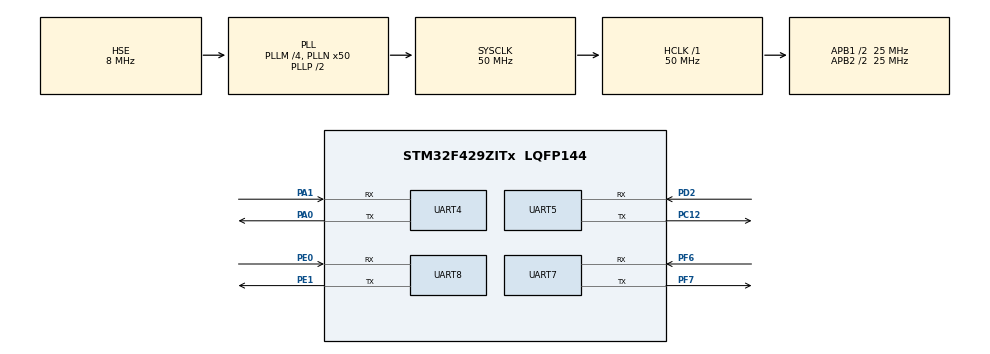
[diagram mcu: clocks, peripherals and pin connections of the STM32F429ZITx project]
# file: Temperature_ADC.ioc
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ADC1.Channel-0\#ChannelRegularConversion=ADC_CHANNEL_TEMPSENSOR
ADC1.ClockPrescaler=ADC_CLOCK_SYNC_PCLK_DIV4
ADC1.ContinuousConvMode=ENABLE
ADC1.DMAContinuousRequests=ENABLE
ADC1.NbrOfConversion=1
ADC1.NbrOfConversionFlag=1
ADC1.Rank-0\#ChannelRegularConversion=1
ADC1.SamplingTime-0\#ChannelRegularConversion=ADC_SAMPLETIME_112CYCLES
ADC1.master=1
Dma.ADC1.0.Direction=DMA_PERIPH_TO_MEMORY
Dma.ADC1.0.FIFOMode=DMA_FIFOMODE_DISABLE
Dma.ADC1.0.Instance=DMA2_Stream0
Dma.ADC1.0.MemDataAlignment=DMA_MDATAALIGN_WORD
Dma.ADC1.0.MemInc=DMA_MINC_ENABLE
Dma.ADC1.0.Mode=DMA_CIRCULAR
Dma.ADC1.0.PeriphDataAlignment=DMA_PDATAALIGN_WORD
Dma.ADC1.0.PeriphInc=DMA_PINC_DISABLE
Dma.ADC1.0.Priority=DMA_PRIORITY_LOW
Dma.Request0=ADC1
Mcu.Family=STM32F4
Mcu.Name=STM32F429ZITx
Mcu.Package=LQFP144
NVIC.DMA2_Stream0_IRQn=true\:0\:0\:false\:false\:true\:false\:true\:true
NVIC.PriorityGroup=NVIC_PRIORITYGROUP_4
PA0/WKUP.Mode=Asynchronous
PA0/WKUP.Signal=UART4_TX
PA1.Mode=Asynchronous
PA1.Signal=UART4_RX
PA13.Mode=Serial_Wire
PA13.Signal=SYS_JTMS-SWDIO
PA14.Mode=Serial_Wire
PA14.Signal=SYS_JTCK-SWCLK
PA2.Signal=USART2_TX
PA3.Signal=USART2_RX
PC12.Mode=Asynchronous
PC12.Signal=UART5_TX
PD2.Mode=Asynchronous
PD2.Signal=UART5_RX
PE0.Mode=Asynchronous
PE0.Signal=UART8_RX
PE1.Mode=Asynchronous
PE1.Signal=UART8_TX
PF6.Mode=Asynchronous
PF6.Signal=UART7_RX
PF7.Mode=Asynchronous
PF7.Signal=UART7_TX
PH0/OSC_IN.Mode=HSE-External-Oscillator
PH0/OSC_IN.Signal=RCC_OSC_IN
PH1/OSC_OUT.Mode=HSE-External-Oscillator
PH1/OSC_OUT.Signal=RCC_OSC_OUT
ProjectManager.HeapSize=0x200
ProjectManager.StackSize=0x400
ProjectManager.TargetToolchain=STM32CubeIDE
RCC.48MHZClocksFreq_Value=25000000
RCC.AHBFreq_Value=50000000
RCC.APB1CLKDivider=RCC_HCLK_DIV2
RCC.APB1Freq_Value=25000000
RCC.APB1TimFreq_Value=50000000
RCC.APB2CLKDivider=RCC_HCLK_DIV2
RCC.APB2Freq_Value=25000000
RCC.APB2TimFreq_Value=50000000
RCC.CortexFreq_Value=50000000
RCC.HCLKFreq_Value=50000000
RCC.HSE_VALUE=8000000
RCC.HSI_VALUE=16000000
RCC.LSE_VALUE=32768
RCC.PLLM=4
RCC.PLLN=50
RCC.PLLSourceVirtual=RCC_PLLSOURCE_HSE
RCC.SYSCLKFreq_VALUE=50000000
RCC.SYSCLKSource=RCC_SYSCLKSOURCE_PLLCLK
RCC.VCOOutputFreq_Value=100000000
UART4.VirtualMode=Asynchronous
UART5.VirtualMode=Asynchronous
UART7.VirtualMode=Asynchronous
UART8.VirtualMode=Asynchronous
VP_ADC1_TempSens_Input.Mode=IN-TempSens
board=custom

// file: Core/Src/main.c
/* USER CODE BEGIN Header */
/**
  ******************************************************************************
  * @file           : main.c
  * @brief          : Main program body
  ******************************************************************************
  * @attention
  *
  * Copyright (c) 2024 STMicroelectronics.
  * All rights reserved.
  *
  * This software is licensed under terms that can be found in the LICENSE file
  * in the root directory of this software component.
  * If no LICENSE file comes with this software, it is provided AS-IS.
  *
  ******************************************************************************
  */
/* USER CODE END Header */
#include "main.h"

/* USER CODE BEGIN Includes */
#include <stdio.h>
/* USER CODE END Includes */

ADC_HandleTypeDef hadc1;
DMA_HandleTypeDef hdma_adc1;

UART_HandleTypeDef huart4;
UART_HandleTypeDef huart5;
UART_HandleTypeDef huart7;
UART_HandleTypeDef huart8;

void SystemClock_Config(void);
static void MX_GPIO_Init(void);
static void MX_DMA_Init(void);
static void MX_ADC1_Init(void);
static void MX_UART4_Init(void);
static void MX_UART5_Init(void);
static void MX_UART7_Init(void);
static void MX_UART8_Init(void);
/* USER CODE BEGIN PFP */

// unable to find inbuilt uart port for nucleo board.
int _write(int file, char *ptr, int len)
{
   HAL_UART_Transmit(&huart8, (uint8_t *)ptr, len, HAL_MAX_DELAY);
   return len;
}

/* USER CODE END PFP */

/* USER CODE BEGIN 0 */

#define Avg_Slope .0025   // V/C
#define V25  0.76   // V
#define VSENSE 3.3/4096  // 12 bit res

uint32_t ADC_VAL = 0;
float Temp = 0;

void HAL_ADC_ConvCpltCallback(ADC_HandleTypeDef* hadc)
{
	Temp =  ((VSENSE*ADC_VAL - V25) / Avg_Slope) + 25;
	printf("Temp value is %0.2f\n", Temp);
}

/* USER CODE END 0 */

int main(void)
{

  /* MCU Configuration--------------------------------------------------------*/

  /* Reset of all peripherals, Initializes the Flash interface and the Systick. */
  HAL_Init();

  /* Configure the system clock */
  SystemClock_Config();

  /* Initialize all configured peripherals */
  MX_GPIO_Init();
  MX_DMA_Init();
  MX_ADC1_Init();
  MX_UART4_Init();
  MX_UART5_Init();
  MX_UART7_Init();
  MX_UART8_Init();
  /* USER CODE BEGIN 2 */

  HAL_ADC_Start_DMA(&hadc1, &ADC_VAL, 1);
  printf("Hello\n");

  /* USER CODE END 2 */

  /* Infinite loop */
  while (1)
  {

  }
}

void SystemClock_Config(void)
{
  RCC_OscInitTypeDef RCC_OscInitStruct = {0};
  RCC_ClkInitTypeDef RCC_ClkInitStruct = {0};

  /** Configure the main internal regulator output voltage
  */
  __HAL_RCC_PWR_CLK_ENABLE();
  __HAL_PWR_VOLTAGESCALING_CONFIG(PWR_REGULATOR_VOLTAGE_SCALE3);

  /** Initializes the RCC Oscillators according to the specified parameters
  * in the RCC_OscInitTypeDef structure.
  */
  RCC_OscInitStruct.OscillatorType = RCC_OSCILLATORTYPE_HSE;
  RCC_OscInitStruct.HSEState = RCC_HSE_ON;
  RCC_OscInitStruct.PLL.PLLState = RCC_PLL_ON;
  RCC_OscInitStruct.PLL.PLLSource = RCC_PLLSOURCE_HSE;
  RCC_OscInitStruct.PLL.PLLM = 4;
  RCC_OscInitStruct.PLL.PLLN = 50;
  RCC_OscInitStruct.PLL.PLLP = RCC_PLLP_DIV2;
  RCC_OscInitStruct.PLL.PLLQ = 4;
  if (HAL_RCC_OscConfig(&RCC_OscInitStruct) != HAL_OK)
  {
    Error_Handler();
  }

  /** Initializes the CPU, AHB and APB buses clocks
  */
  RCC_ClkInitStruct.ClockType = RCC_CLOCKTYPE_HCLK|RCC_CLOCKTYPE_SYSCLK
                              |RCC_CLOCKTYPE_PCLK1|RCC_CLOCKTYPE_PCLK2;
  RCC_ClkInitStruct.SYSCLKSource = RCC_SYSCLKSOURCE_PLLCLK;
  RCC_ClkInitStruct.AHBCLKDivider = RCC_SYSCLK_DIV1;
  RCC_ClkInitStruct.APB1CLKDivider = RCC_HCLK_DIV2;
  RCC_ClkInitStruct.APB2CLKDivider = RCC_HCLK_DIV2;

  if (HAL_RCC_ClockConfig(&RCC_ClkInitStruct, FLASH_LATENCY_1) != HAL_OK)
  {
    Error_Handler();
  }
}

static void MX_ADC1_Init(void)
{

  ADC_ChannelConfTypeDef sConfig = {0};

  /** Configure the global features of the ADC (Clock, Resolution, Data Alignment and number of conversion)
  */
  hadc1.Instance = ADC1;
  hadc1.Init.ClockPrescaler = ADC_CLOCK_SYNC_PCLK_DIV4;
  hadc1.Init.Resolution = ADC_RESOLUTION_12B;
  hadc1.Init.ScanConvMode = DISABLE;
  hadc1.Init.ContinuousConvMode = ENABLE;
  hadc1.Init.DiscontinuousConvMode = DISABLE;
  hadc1.Init.ExternalTrigConvEdge = ADC_EXTERNALTRIGCONVEDGE_NONE;
  hadc1.Init.ExternalTrigConv = ADC_SOFTWARE_START;
  hadc1.Init.DataAlign = ADC_DATAALIGN_RIGHT;
  hadc1.Init.NbrOfConversion = 1;
  hadc1.Init.DMAContinuousRequests = ENABLE;
  hadc1.Init.EOCSelection = ADC_EOC_SINGLE_CONV;
  if (HAL_ADC_Init(&hadc1) != HAL_OK)
  {
    Error_Handler();
  }

  /** Configure for the selected ADC regular channel its corresponding rank in the sequencer and its sample time.
  */
  sConfig.Channel = ADC_CHANNEL_TEMPSENSOR;
  sConfig.Rank = 1;
  sConfig.SamplingTime = ADC_SAMPLETIME_112CYCLES;
  if (HAL_ADC_ConfigChannel(&hadc1, &sConfig) != HAL_OK)
  {
    Error_Handler();
  }

}

static void MX_UART4_Init(void)
{

  huart4.Instance = UART4;
  huart4.Init.BaudRate = 115200;
  huart4.Init.WordLength = UART_WORDLENGTH_8B;
  huart4.Init.StopBits = UART_STOPBITS_1;
  huart4.Init.Parity = UART_PARITY_NONE;
  huart4.Init.Mode = UART_MODE_TX_RX;
  huart4.Init.HwFlowCtl = UART_HWCONTROL_NONE;
  huart4.Init.OverSampling = UART_OVERSAMPLING_16;
  if (HAL_UART_Init(&huart4) != HAL_OK)
  {
    Error_Handler();
  }

}

static void MX_UART5_Init(void)
{

  huart5.Instance = UART5;
  huart5.Init.BaudRate = 115200;
  huart5.Init.WordLength = UART_WORDLENGTH_8B;
  huart5.Init.StopBits = UART_STOPBITS_1;
  huart5.Init.Parity = UART_PARITY_NONE;
  huart5.Init.Mode = UART_MODE_TX_RX;
  huart5.Init.HwFlowCtl = UART_HWCONTROL_NONE;
  huart5.Init.OverSampling = UART_OVERSAMPLING_16;
  if (HAL_UART_Init(&huart5) != HAL_OK)
  {
    Error_Handler();
  }

}

static void MX_UART7_Init(void)
{

  huart7.Instance = UART7;
  huart7.Init.BaudRate = 115200;
  huart7.Init.WordLength = UART_WORDLENGTH_8B;
  huart7.Init.StopBits = UART_STOPBITS_1;
  huart7.Init.Parity = UART_PARITY_NONE;
  huart7.Init.Mode = UART_MODE_TX_RX;
  huart7.Init.HwFlowCtl = UART_HWCONTROL_NONE;
  huart7.Init.OverSampling = UART_OVERSAMPLING_16;
  if (HAL_UART_Init(&huart7) != HAL_OK)
  {
    Error_Handler();
  }

}

static void MX_UART8_Init(void)
{

  huart8.Instance = UART8;
  huart8.Init.BaudRate = 115200;
  huart8.Init.WordLength = UART_WORDLENGTH_8B;
  huart8.Init.StopBits = UART_STOPBITS_1;
  huart8.Init.Parity = UART_PARITY_NONE;
  huart8.Init.Mode = UART_MODE_TX_RX;
  huart8.Init.HwFlowCtl = UART_HWCONTROL_NONE;
  huart8.Init.OverSampling = UART_OVERSAMPLING_16;
  if (HAL_UART_Init(&huart8) != HAL_OK)
  {
    Error_Handler();
  }

}

static void MX_DMA_Init(void)
{

  /* DMA controller clock enable */
  __HAL_RCC_DMA2_CLK_ENABLE();

  /* DMA interrupt init */
  /* DMA2_Stream0_IRQn interrupt configuration */
  HAL_NVIC_SetPriority(DMA2_Stream0_IRQn, 0, 0);
  HAL_NVIC_EnableIRQ(DMA2_Stream0_IRQn);

}

static void MX_GPIO_Init(void)
{
  GPIO_InitTypeDef GPIO_InitStruct = {0};

  /* GPIO Ports Clock Enable */
  __HAL_RCC_GPIOF_CLK_ENABLE();
  __HAL_RCC_GPIOH_CLK_ENABLE();
  __HAL_RCC_GPIOA_CLK_ENABLE();
  __HAL_RCC_GPIOC_CLK_ENABLE();
  __HAL_RCC_GPIOD_CLK_ENABLE();
  __HAL_RCC_GPIOE_CLK_ENABLE();

  /*Configure GPIO pins : PA2 PA3 */
  GPIO_InitStruct.Pin = GPIO_PIN_2|GPIO_PIN_3;
  GPIO_InitStruct.Mode = GPIO_MODE_AF_PP;
  GPIO_InitStruct.Pull = GPIO_NOPULL;
  GPIO_InitStruct.Speed = GPIO_SPEED_FREQ_VERY_HIGH;
  GPIO_InitStruct.Alternate = GPIO_AF7_USART2;
  HAL_GPIO_Init(GPIOA, &GPIO_InitStruct);

}

void Error_Handler(void)
{
  __disable_irq();
  while (1)
  {
  }
}
